# PIC24FJ256GB110 register map
Vendor: Microchip
Registers are 16-bit, read-write, reset 0x0 unless marked. A register's access mark holds for its fields unless they carry their own. Addresses are absolute, and some are shared; only a register's first bit layout is shown; [hi:lo] are bit positions.

## CONFIG — Configuration words, addresses in ProgramSpace
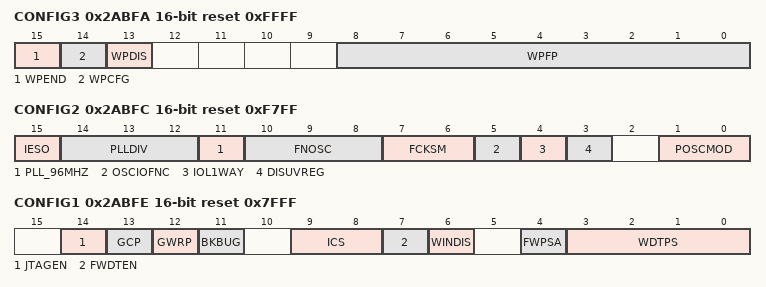
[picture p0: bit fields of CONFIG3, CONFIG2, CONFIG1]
0x2ABFA CONFIG3 reset 0xFFFF
  [15] WPEND — Segment Write Protection End Page Select bit
    1=WPENDMEM (Write Protect from WPFP to the last page of memory); 0=WPSTARTMEM (Write Protect from page 0 to WPFP)
  [14] WPCFG — Configuration Word Code Page Protection Select bit
    1=WPCFGDIS (Last page(at the top of program memory) and Flash configuration words are not protected); 0=WPCFGEN (Last page and Flash configuration words are code-protected)
  [13] WPDIS — Segment Write Protection Disable bit
    1=WPDIS (Segmented code protection disabled); 0=WPEN (Segmented code protection enabled)
  [8:0] WPFP — Write Protection Flash Page Segment Boundary
    0=Page 0 (0x00); 1=Page 1 (0x400); 2=Page 2 (0x800); 3=Page 3 (0xC00); 4=Page 4 (0x1000); 5=Page 5 (0x1400); 6=Page 6 (0x1800); 7=Page 7 (0x1C00); 8=Page 8 (0x2000); 9=Page 9 (0x2400); 10=Page 10 (0x2800); 11=Page 11 (0x2C00); 12=Page 12 (0x3000); 13=Page 13 (0x3400); 14=Page 14 (0x3800); 15=Page 15 (0x3C00); 16=Page 16 (0x4000); 17=Page 17 (0x4400); 18=Page 18 (0x4800); 19=Page 19 (0x4C00); 20=Page 20 (0x5000); 21=Page 21 (0x5400); 22=Page 22 (0x5800); 23=Page 23 (0x5C00); 24=Page 24 (0x6000); 25=Page 25 (0x6400); 26=Page 26 (0x6800); 27=Page 27 (0x6C00); 28=Page 28 (0x7000); 29=Page 29 (0x7400); 30=Page 30 (0x7800); 31=Page 31 (0x7C00); 32=Page 32 (0x8000); 33=Page 33 (0x8400); 34=Page 34 (0x8800); 35=Page 35 (0x8C00); 36=Page 36 (0x9000); 37=Page 37 (0x9400); 38=Page 38 (0x9800); 39=Page 39 (0x9C00); 40=Page 40 (0xA000); 41=Page 41 (0xA400); 42=Page 42 (0xA800); 43=Page 43 (0xAC00); 44=Page 44 (0xB000); 45=Page 45 (0xB400); 46=Page 46 (0xB800); 47=Page 47 (0xBC00); 48=Page 48 (0xC000); 49=Page 49 (0xC400); 50=Page 50 (0xC800); 51=Page 51 (0xCC00); 52=Page 52 (0xD000); 53=Page 53 (0xD400); 54=Page 54 (0xD800); 55=Page 55 (0xDC00); 56=Page 56 (0xE000); 57=Page 57 (0xE400); 58=Page 58 (0xE800); 59=Page 59 (0xEC00); 60=Page 60 (0xF000); 61=Page 61 (0xF400); 62=Page 62 (0xF800); 63=Page 63 (0xFC00); 64=Page 64 (0x10000); 65=Page 65 (0x10400); 66=Page 66 (0x10800); 67=Page 67 (0x10C00); 68=Page 68 (0x11000); 69=Page 69 (0x11400); 70=Page 70 (0x11800); 71=Page 71 (0x11C00); 72=Page 72 (0x12000); 73=Page 73 (0x12400); 74=Page 74 (0x12800); 75=Page 75 (0x12C00); 76=Page 76 (0x13000); 77=Page 77 (0x13400); 78=Page 78 (0x13800); 79=Page 79 (0x13C00); 80=Page 80 (0x14000); 81=Page 81 (0x14400); 82=Page 82 (0x14800); 83=Page 83 (0x14C00); 84=Page 84 (0x15000); 85=Page 85 (0x15400); 86=Page 86 (0x15800); 87=Page 87 (0x15C00); 88=Page 88 (0x16000); 89=Page 89 (0x16400); 90=Page 90 (0x16800); 91=Page 91 (0x16C00); 92=Page 92 (0x17000); 93=Page 93 (0x17400); 94=Page 94 (0x17800); 95=Page 95 (0x17C00); 96=Page 96 (0x18000); 97=Page 97 (0x18400); 98=Page 98 (0x18800); 99=Page 99 (0x18C00); 100=Page 100 (0x19000); 101=Page 101 (0x19400); 102=Page 102 (0x19800); 103=Page 103 (0x19C00); 104=Page 104 (0x1A000); 105=Page 105 (0x1A400); 106=Page 106 (0x1A800); 107=Page 107 (0x1AC00); 108=Page 108 (0x1B000); 109=Page 109 (0x1B400); 110=Page 110 (0x1B800); 111=Page 111 (0x1BC00); 112=Page 112 (0x1C000); 113=Page 113 (0x1C400); 114=Page 114 (0x1C800); 115=Page 115 (0x1CC00); 116=Page 116 (0x1D000); 117=Page 117 (0x1D400); 118=Page 118 (0x1D800); 119=Page 119 (0x1DC00); 120=Page 120 (0x1E000); 121=Page 121 (0x1E400); 122=Page 122 (0x1E800); 123=Page 123 (0x1EC00); 124=Page 124 (0x1F000); 125=Page 125 (0x1F400); 126=Page 126 (0x1F800); 127=Page 127 (0x1FC00); 128=Page 128 (0x20000); 129=Page 129 (0x20400); 130=Page 130 (0x20800); 131=Page 131 (0x20C00); 132=Page 132 (0x21000); 133=Page 133 (0x21400); 134=Page 134 (0x21800); 135=Page 135 (0x21C00); 136=Page 136 (0x22000); 137=Page 137 (0x22400); 138=Page 138 (0x22800); 139=Page 139 (0x22C00); 140=Page 140 (0x23000); 141=Page 141 (0x23400); 142=Page 142 (0x23800); 143=Page 143 (0x23C00); 144=Page 144 (0x24000); 145=Page 145 (0x24400); 146=Page 146 (0x24800); 147=Page 147 (0x24C00); 148=Page 148 (0x25000); 149=Page 149 (0x25400); 150=Page 150 (0x25800); 151=Page 151 (0x25C00); 152=Page 152 (0x26000); 153=Page 153 (0x26400); 154=Page 154 (0x26800); 155=Page 155 (0x26C00); 156=Page 156 (0x27000); 157=Page 157 (0x27400); 158=Page 158 (0x27800); 159=Page 159 (0x27C00); 160=Page 160 (0x28000); 161=Page 161 (0x28400); 162=Page 162 (0x28800); 163=Page 163 (0x28C00); 164=Page 164 (0x29000); 165=Page 165 (0x29400); 166=Page 166 (0x29800); 167=Page 167 (0x29C00); 168=Page 168 (0x2A000); 169=Page 169 (0x2A400); 170=Page 170 (0x2A800); 0x1FF=Highest Page (same as page 170)
0x2ABFC CONFIG2 reset 0xF7FF
  [15] IESO — Internal External Switch Over Mode
    0=OFF (IESO mode (Two-speed start-up)disabled); 1=ON (IESO mode (Two-speed start-up) enabled)
  [14:12] PLLDIV — USB 96 MHz PLL Prescaler Select bits
    7=DIV12 (Oscillator input divided by 12 (48MHz input)); 6=DIV10 (Oscillator input divided by 10 (40MHz input)); 5=DIV6 (Oscillator input divided by 6 (24MHz input)); 4=DIV5 (Oscillator input divided by 5 (20MHz input)); 3=DIV4 (Oscillator input divided by 4 (16MHz input)); 2=DIV3 (Oscillator input divided by 3 (12MHz input)); 1=DIV2 (Oscillator input divided by 2 (8MHz input)); 0=NODIV (Oscillator input used directly (4MHz input))
  [11] PLL_96MHZ ro — 96MHz PLL Disable
    0=ON (Enabled)
  [10:8] FNOSC — Oscillator Select
    7=FRCDIV (Fast RC oscillator with Postscaler (FRCDIV)); 5=LPRC (Low-Power RC oscillator (LPRC)); 4=SOSC (Secondary oscillator (SOSC)); 3=PRIPLL (Primary oscillator (XT, HS, EC) with PLL module (XTPLL,HSPLL, ECPLL)); 2=PRI (Primary oscillator (XT, HS, EC)); 1=FRCPLL (Fast RC oscillator with Postscaler and PLL module (FRCPLL)); 0=FRC (Fast RC Oscillator (FRC))
  [7:6] FCKSM — Clock Switching and Monitor
    0b1x=CSDCMD (Both Clock Switching and Fail-safe Clock Monitor are disabled); 1=CSECMD (Clock switching is enabled, Fail-safe Clock Monitor is disabled); 0=CSECME (Both Clock switching and Fail-safe Clock Monitor are enabled)
  [5] OSCIOFNC — Primary Oscillator Output Function
    0=ON (OSCO functions as port I/O (RC15)); 1=OFF (OSCO functions as CLKO (FOSC/2))
  [4] IOL1WAY — IOLOCK One-Way Set Enable bit
    0=OFF (Unlimited Writes To RP Registers); 1=ON (Write RP Registers Once)
  [3] DISUVREG — Internal USB 3.3V Regulator Disable bit
    1=OFF (Regulator is disabled); 0=ON (Regulator is enabled)
  [1:0] POSCMOD — Primary Oscillator Select
    3=NONE (Primary oscillator disabled); 2=HS (HS oscillator mode selected); 1=XT (XT oscillator mode selected); 0=EC (EC oscillator mode selected)
0x2ABFE CONFIG1 reset 0x7FFF
  [14] JTAGEN — JTAG Port Enable
    1=ON (JTAG port is enabled); 0=OFF (JTAG port is disabled)
  [13] GCP — General Code Segment Code Protect
    1=OFF (Code protection is disabled); 0=ON (Code protection is enabled for the entire program memory space)
  [12] GWRP — General Code Segment Write Protect
    1=OFF (Writes to program memory are allowed); 0=ON (Writes to program memory are disabled)
  [11] BKBUG — Background Debug
    1=OFF (Device resets into Operational mode); 0=ON (Device resets into Debug mode)
  [9:8] ICS — Comm Channel Select
    1=PGx3 (Emulator functions are shared with PGEC3/PGED3); 2=PGx2 (Emulator functions are shared with PGEC2/PGED2); 3=PGx1 (Emulator functions are shared with PGEC1/PGED1)
  [7] FWDTEN — Watchdog Timer Enable
    1=ON (Watchdog Timer is enabled); 0=OFF (Watchdog Timer is disabled)
  [6] WINDIS — Watchdog Timer Window
    1=OFF (Standard Watchdog Timer enabled,(Windowed-mode is disabled)); 0=ON (Windowed Watchdog Timer enabled; FWDTEN must be 1)
  [4] FWPSA — WDT Prescaler
    1=PR128 (Prescaler ratio of 1:128); 0=PR32 (Prescaler ratio of 1:32)
  [3:0] WDTPS — Watchdog Timer Postscaler
    15=PS32768 (1:32,768); 14=PS16384 (1:16,384); 13=PS8192 (1:8,192); 12=PS4096 (1:4,096); 11=PS2048 (1:2,048); 10=PS1024 (1:1,024); 9=PS512 (1:512); 8=PS256 (1:256); 7=PS128 (1:128); 6=PS64 (1:64); 5=PS32 (1:32); 4=PS16 (1:16); 3=PS8 (1:8); 2=PS4 (1:4); 1=PS2 (1:2); 0=PS1 (1:1)
